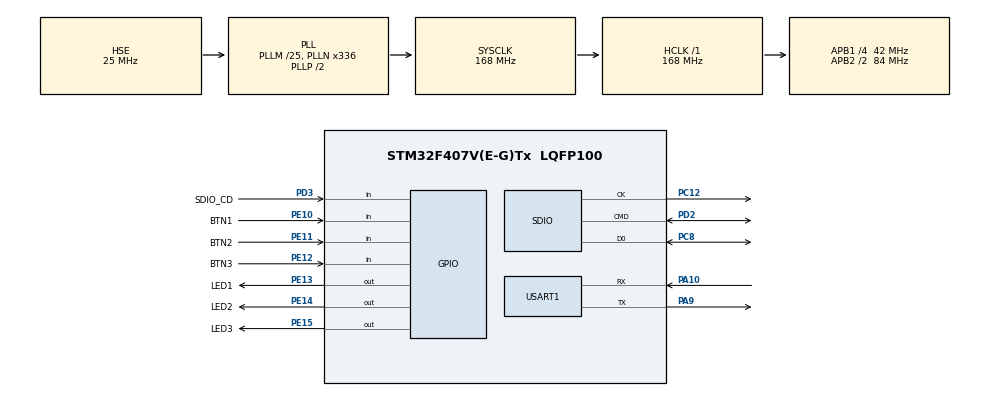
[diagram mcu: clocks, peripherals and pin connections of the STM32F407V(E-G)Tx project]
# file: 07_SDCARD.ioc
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Dma.Request0=SDIO
Dma.SDIO.0.Direction=DMA_PERIPH_TO_MEMORY
Dma.SDIO.0.FIFOMode=DMA_FIFOMODE_ENABLE
Dma.SDIO.0.FIFOThreshold=DMA_FIFO_THRESHOLD_FULL
Dma.SDIO.0.Instance=DMA2_Stream3
Dma.SDIO.0.MemBurst=DMA_MBURST_INC4
Dma.SDIO.0.MemDataAlignment=DMA_MDATAALIGN_WORD
Dma.SDIO.0.MemInc=DMA_MINC_ENABLE
Dma.SDIO.0.Mode=DMA_PFCTRL
Dma.SDIO.0.PeriphBurst=DMA_PBURST_INC4
Dma.SDIO.0.PeriphDataAlignment=DMA_PDATAALIGN_WORD
Dma.SDIO.0.PeriphInc=DMA_PINC_DISABLE
Dma.SDIO.0.Priority=DMA_PRIORITY_LOW
FATFS.BSP.number=1
FATFS.USE_DMA_CODE_SD=1
FATFS0.BSP.STBoard=false
FATFS0.BSP.api=Unknown
FATFS0.BSP.instance=PD3
FATFS0.BSP.ip=GPIO
FATFS0.BSP.mode=Input
FATFS0.BSP.name=Detect_SDIO
FATFS0.BSP.solution=PD3
Mcu.Family=STM32F4
Mcu.Name=STM32F407V(E-G)Tx
Mcu.Package=LQFP100
NVIC.DMA2_Stream3_IRQn=true\:0\:0\:false\:false\:true\:false\:true\:true
NVIC.PriorityGroup=NVIC_PRIORITYGROUP_4
NVIC.SDIO_IRQn=true\:0\:0\:false\:false\:true\:true\:true\:true
NVIC.USART1_IRQn=true\:0\:0\:false\:false\:true\:true\:true\:true
PA10.Mode=Asynchronous
PA10.Signal=USART1_RX
PA13.Mode=JTAG_5_pins
PA13.Signal=SYS_JTMS-SWDIO
PA14.Mode=JTAG_5_pins
PA14.Signal=SYS_JTCK-SWCLK
PA15.Mode=JTAG_5_pins
PA15.Signal=SYS_JTDI
PA9.Mode=Asynchronous
PA9.Signal=USART1_TX
PB3.Mode=JTAG_5_pins
PB3.Signal=SYS_JTDO-SWO
PB4.Mode=JTAG_5_pins
PB4.Signal=SYS_JTRST
PC12.Mode=SD_1_bit
PC12.Signal=SDIO_CK
PC14-OSC32_IN.Mode=LSE-External-Oscillator
PC14-OSC32_IN.Signal=RCC_OSC32_IN
PC15-OSC32_OUT.Mode=LSE-External-Oscillator
PC15-OSC32_OUT.Signal=RCC_OSC32_OUT
PC8.Mode=SD_1_bit
PC8.Signal=SDIO_D0
PD2.Mode=SD_1_bit
PD2.Signal=SDIO_CMD
PD3.GPIO_Label=SDIO_CD
PD3.Signal=GPIO_Input
PE10.GPIO_Label=BTN1
PE10.Signal=GPIO_Input
PE11.GPIO_Label=BTN2
PE11.Signal=GPIO_Input
PE12.GPIO_Label=BTN3
PE12.Signal=GPIO_Input
PE13.GPIO_Label=LED1
PE13.Signal=GPIO_Output
PE14.GPIO_Label=LED2
PE14.PinState=GPIO_PIN_SET
PE14.Signal=GPIO_Output
PE15.GPIO_Label=LED3
PE15.PinState=GPIO_PIN_SET
PE15.Signal=GPIO_Output
PH0-OSC_IN.Mode=HSE-External-Oscillator
PH0-OSC_IN.Signal=RCC_OSC_IN
PH1-OSC_OUT.Mode=HSE-External-Oscillator
PH1-OSC_OUT.Signal=RCC_OSC_OUT
ProjectManager.HeapSize=0x200
ProjectManager.StackSize=0x400
ProjectManager.TargetToolchain=STM32CubeIDE
RCC.48MHZClocksFreq_Value=48000000
RCC.AHBFreq_Value=168000000
RCC.APB1CLKDivider=RCC_HCLK_DIV4
RCC.APB1Freq_Value=42000000
RCC.APB1TimFreq_Value=84000000
RCC.APB2CLKDivider=RCC_HCLK_DIV2
RCC.APB2Freq_Value=84000000
RCC.APB2TimFreq_Value=168000000
RCC.CortexFreq_Value=168000000
RCC.HCLKFreq_Value=168000000
RCC.HSE_VALUE=25000000
RCC.HSI_VALUE=16000000
RCC.PLLM=25
RCC.PLLN=336
RCC.PLLQ=7
RCC.PLLSourceVirtual=RCC_PLLSOURCE_HSE
RCC.SYSCLKFreq_VALUE=168000000
RCC.SYSCLKSource=RCC_SYSCLKSOURCE_PLLCLK
RCC.VCOOutputFreq_Value=336000000
SDIO.ClockDiv=3
SDIO.ClockPowerSave=SDIO_CLOCK_POWER_SAVE_ENABLE
SDIO.HardwareFlowControl=SDIO_HARDWARE_FLOW_CONTROL_ENABLE
USART1.VirtualMode=VM_ASYNC
VP_FATFS_VS_SDIO.Mode=SDIO
board=custom

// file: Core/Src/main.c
/* USER CODE BEGIN Header */
/**
  ******************************************************************************
  * @file           : main.c
  * @brief          : Main program body
  ******************************************************************************
  * @attention
  *
  * Copyright (c) 2025 STMicroelectronics.
  * All rights reserved.
  *
  * This software is licensed under terms that can be found in the LICENSE file
  * in the root directory of this software component.
  * If no LICENSE file comes with this software, it is provided AS-IS.
  *
  ******************************************************************************
  */
/* USER CODE END Header */
#include "main.h"
#include "dma.h"
#include "fatfs.h"
#include "sdio.h"
#include "usart.h"
#include "gpio.h"

/* USER CODE BEGIN Includes */
#include <stdio.h>
/* USER CODE END Includes */

/* USER CODE BEGIN PV */
extern UART_HandleTypeDef huart1;
/* USER CODE END PV */

void SystemClock_Config(void);

/* USER CODE BEGIN 0 */
int __io_putchar(int ch)
{
  if(HAL_UART_Transmit(&huart1, (uint8_t *)&ch, 1, 10) != HAL_OK)
  {
    return -1;
  }
  return ch;
}

//uint8_t rxbuf;
//void HAL_UART_RxCpltCallback(UART_HandleTypeDef *huart)
//{
//  if (huart->Instance == USART1)
//  {
//    // to UART1
//    HAL_UART_Transmit(huart, (uint8_t *)&rxbuf, 1, 10);
//    HAL_UART_Receive_IT(huart, &rxbuf, 1);
//  }
//}
/* USER CODE END 0 */

int main(void)
{

  /* MCU Configuration--------------------------------------------------------*/

  /* Reset of all peripherals, Initializes the Flash interface and the Systick. */
  HAL_Init();

  /* Configure the system clock */
  SystemClock_Config();

  /* Initialize all configured peripherals */
  MX_GPIO_Init();
  MX_DMA_Init();
  MX_USART1_UART_Init();
  MX_SDIO_SD_Init();
  MX_FATFS_Init();

  /* USER CODE BEGIN 2 */
  printf("\r\nInit Complete.\r\n");
  printf("Checking Storage Devices:\r\n");
  MX_SDIO_SD_Check();

  /* USER CODE END 2 */

  /* Infinite loop */
  while (1)
  {

  }
}

void SystemClock_Config(void)
{
  RCC_OscInitTypeDef RCC_OscInitStruct = {0};
  RCC_ClkInitTypeDef RCC_ClkInitStruct = {0};

  /** Configure the main internal regulator output voltage
  */
  __HAL_RCC_PWR_CLK_ENABLE();
  __HAL_PWR_VOLTAGESCALING_CONFIG(PWR_REGULATOR_VOLTAGE_SCALE1);

  /** Initializes the RCC Oscillators according to the specified parameters
  * in the RCC_OscInitTypeDef structure.
  */
  RCC_OscInitStruct.OscillatorType = RCC_OSCILLATORTYPE_HSE;
  RCC_OscInitStruct.HSEState = RCC_HSE_ON;
  RCC_OscInitStruct.PLL.PLLState = RCC_PLL_ON;
  RCC_OscInitStruct.PLL.PLLSource = RCC_PLLSOURCE_HSE;
  RCC_OscInitStruct.PLL.PLLM = 25;
  RCC_OscInitStruct.PLL.PLLN = 336;
  RCC_OscInitStruct.PLL.PLLP = RCC_PLLP_DIV2;
  RCC_OscInitStruct.PLL.PLLQ = 7;
  if (HAL_RCC_OscConfig(&RCC_OscInitStruct) != HAL_OK)
  {
    Error_Handler();
  }

  /** Initializes the CPU, AHB and APB buses clocks
  */
  RCC_ClkInitStruct.ClockType = RCC_CLOCKTYPE_HCLK|RCC_CLOCKTYPE_SYSCLK
                              |RCC_CLOCKTYPE_PCLK1|RCC_CLOCKTYPE_PCLK2;
  RCC_ClkInitStruct.SYSCLKSource = RCC_SYSCLKSOURCE_PLLCLK;
  RCC_ClkInitStruct.AHBCLKDivider = RCC_SYSCLK_DIV1;
  RCC_ClkInitStruct.APB1CLKDivider = RCC_HCLK_DIV4;
  RCC_ClkInitStruct.APB2CLKDivider = RCC_HCLK_DIV2;

  if (HAL_RCC_ClockConfig(&RCC_ClkInitStruct, FLASH_LATENCY_5) != HAL_OK)
  {
    Error_Handler();
  }
}

/* USER CODE BEGIN 4 */

/**
  * @brief Override for printf output
  * @param  file: pointer to the source file name
  * @param  ptr: pointer to data to write
  * @param  len: length data to write in bytes
  * @retval Number of bytes written
  */
//int _write(int file, char *ptr, int len)
//{
//    HAL_StatusTypeDef rc;
//
//    do {
//      /* Send the data, retrying if busy */
//      rc = HAL_UART_Transmit(&huart1, (uint8_t *)ptr, len, 100);
//    } while (rc == HAL_BUSY);
//
//    return len;
//}

/* USER CODE END 4 */

void Error_Handler(void)
{
  __disable_irq();
  while (1)
  {
  }
}
